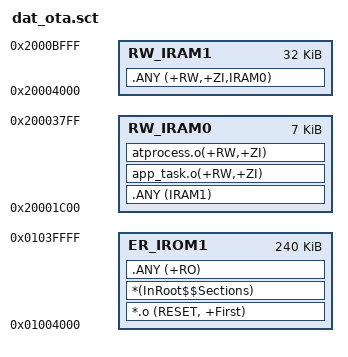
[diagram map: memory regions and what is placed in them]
; *************************************************************
; *** Scatter-Loading Description File generated by uVision ***
; *************************************************************

LR_IROM1 0x01004000 0x0003C000    {    ; load region size_region
  ER_IROM1 0x01004000 0x0003C000  {    ; load address = execution address
   *.o (RESET, +First)
   *(InRoot$$Sections)
   .ANY (+RO)
  }
  
  RW_IRAM0 0x20001c00 0x00001c00  {    ; RW data 0
    .ANY (IRAM1)
    app_task.o(+RW,+ZI)
    atprocess.o(+RW,+ZI)
  } 
  RW_IRAM1 0x20004000 0x00008000  {    ; RW data
    .ANY (+RW,+ZI,IRAM0)
  }
}

